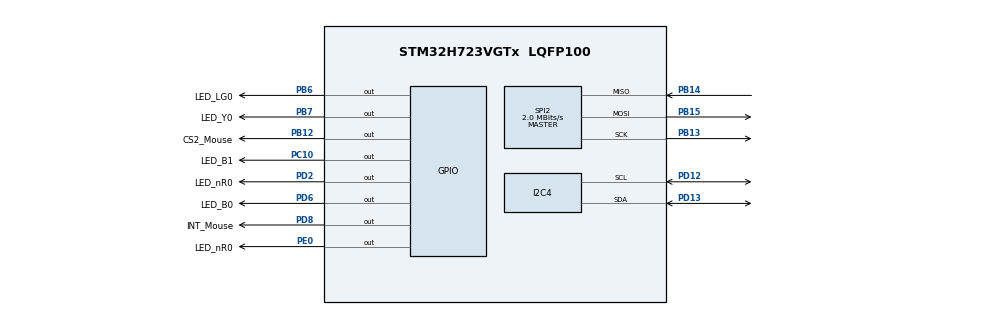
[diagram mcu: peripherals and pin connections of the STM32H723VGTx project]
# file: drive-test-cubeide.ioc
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CORTEX_M7.default_mode_Activation=1
I2C4.Timing=0x00303D5B
Mcu.Family=STM32H7
Mcu.Name=STM32H723VGTx
Mcu.Package=LQFP100
NVIC.PriorityGroup=NVIC_PRIORITYGROUP_4
PB12.GPIO_Label=CS2_Mouse
PB12.Signal=GPIO_Output
PB13.Mode=Full_Duplex_Master
PB13.Signal=SPI2_SCK
PB14.Mode=Full_Duplex_Master
PB14.Signal=SPI2_MISO
PB15.Mode=Full_Duplex_Master
PB15.Signal=SPI2_MOSI
PB6.GPIO_Label=LED_LG0
PB6.Signal=GPIO_Output
PB7.GPIO_Label=LED_Y0
PB7.Signal=GPIO_Output
PC10.GPIO_Label=LED_B1
PC10.Signal=GPIO_Output
PD12.Mode=I2C
PD12.Signal=I2C4_SCL
PD13.Mode=I2C
PD13.Signal=I2C4_SDA
PD2.GPIO_Label=LED_nR0
PD2.Signal=GPIO_Output
PD6.GPIO_Label=LED_B0
PD6.Signal=GPIO_Output
PD8.GPIO_Label=INT_Mouse
PD8.Signal=GPIO_Output
PE0.GPIO_Label=LED_nR0
PE0.Signal=GPIO_Output
PH0-OSC_IN.Mode=HSE-External-Oscillator
PH0-OSC_IN.Signal=RCC_OSC_IN
PH1-OSC_OUT.Mode=HSE-External-Oscillator
PH1-OSC_OUT.Signal=RCC_OSC_OUT
ProjectManager.HeapSize=0x200
ProjectManager.StackSize=0x400
ProjectManager.TargetToolchain=STM32CubeIDE
RCC.ADCFreq_Value=32250000
RCC.APB1Freq_Value=16000000
RCC.APB2Freq_Value=16000000
RCC.APB3Freq_Value=16000000
RCC.APB4Freq_Value=16000000
RCC.CortexFreq_Value=16000000
RCC.DIVM1=1
RCC.DIVN1=12
RCC.DIVQ1=3
RCC.HCLKFreq_Value=16000000
RCC.HSE_VALUE=16000000
RCC.PLLFRACN=0
RCC.PLLSourceVirtual=RCC_PLLSOURCE_HSE
RCC.SYSCLKFreq_VALUE=16000000
RCC.SYSCLKSource=RCC_SYSCLKSOURCE_HSE
RCC.USBFreq_Value=64000000
SPI2.BaudRatePrescaler=SPI_BAUDRATEPRESCALER_32
SPI2.CLKPhase=SPI_PHASE_1EDGE
SPI2.CalculateBaudRate=2.0 MBits/s
SPI2.DataSize=SPI_DATASIZE_8BIT
SPI2.Direction=SPI_DIRECTION_2LINES
SPI2.Mode=SPI_MODE_MASTER
SPI2.NSSPMode=SPI_NSS_PULSE_ENABLE
SPI2.VirtualType=VM_MASTER
VP_MEMORYMAP_VS_MEMORYMAP.Mode=CurAppReg
board=custom

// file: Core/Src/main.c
/* USER CODE BEGIN Header */
/**
  ******************************************************************************
  * @file           : main.c
  * @brief          : Main program body
  ******************************************************************************
  * @attention
  *
  * Copyright (c) 2025 STMicroelectronics.
  * All rights reserved.
  *
  * This software is licensed under terms that can be found in the LICENSE file
  * in the root directory of this software component.
  * If no LICENSE file comes with this software, it is provided AS-IS.
  *
  ******************************************************************************
  */
/* USER CODE END Header */
#include "main.h"
#include "i2c.h"
#include "memorymap.h"
#include "spi.h"
#include "gpio.h"

void SystemClock_Config(void);
static void MPU_Config(void);

int main(void)
{

  /* MPU Configuration--------------------------------------------------------*/
  MPU_Config();

  /* MCU Configuration--------------------------------------------------------*/

  /* Reset of all peripherals, Initializes the Flash interface and the Systick. */
  HAL_Init();

  /* Configure the system clock */
  SystemClock_Config();

  /* Initialize all configured peripherals */
  MX_GPIO_Init();
  MX_I2C4_Init();
  MX_SPI2_Init();
  /* USER CODE BEGIN 2 */
  UserApp_Init();

  /* USER CODE END 2 */

  /* Infinite loop */
  /* USER CODE BEGIN WHILE */
  while (1)
  {
      UserApp_Run();
    /* USER CODE END WHILE */

  }
}

void SystemClock_Config(void)
{
  RCC_OscInitTypeDef RCC_OscInitStruct = {0};
  RCC_ClkInitTypeDef RCC_ClkInitStruct = {0};

  /** Supply configuration update enable
  */
  HAL_PWREx_ConfigSupply(PWR_LDO_SUPPLY);

  /** Configure the main internal regulator output voltage
  */
  __HAL_PWR_VOLTAGESCALING_CONFIG(PWR_REGULATOR_VOLTAGE_SCALE3);

  while(!__HAL_PWR_GET_FLAG(PWR_FLAG_VOSRDY)) {}

  /** Initializes the RCC Oscillators according to the specified parameters
  * in the RCC_OscInitTypeDef structure.
  */
  RCC_OscInitStruct.OscillatorType = RCC_OSCILLATORTYPE_HSE;
  RCC_OscInitStruct.HSEState = RCC_HSE_ON;
  RCC_OscInitStruct.PLL.PLLState = RCC_PLL_ON;
  RCC_OscInitStruct.PLL.PLLSource = RCC_PLLSOURCE_HSE;
  RCC_OscInitStruct.PLL.PLLM = 1;
  RCC_OscInitStruct.PLL.PLLN = 12;
  RCC_OscInitStruct.PLL.PLLP = 2;
  RCC_OscInitStruct.PLL.PLLQ = 3;
  RCC_OscInitStruct.PLL.PLLR = 2;
  RCC_OscInitStruct.PLL.PLLRGE = RCC_PLL1VCIRANGE_3;
  RCC_OscInitStruct.PLL.PLLVCOSEL = RCC_PLL1VCOWIDE;
  RCC_OscInitStruct.PLL.PLLFRACN = 0;
  if (HAL_RCC_OscConfig(&RCC_OscInitStruct) != HAL_OK)
  {
    Error_Handler();
  }

  /** Initializes the CPU, AHB and APB buses clocks
  */
  RCC_ClkInitStruct.ClockType = RCC_CLOCKTYPE_HCLK|RCC_CLOCKTYPE_SYSCLK
                              |RCC_CLOCKTYPE_PCLK1|RCC_CLOCKTYPE_PCLK2
                              |RCC_CLOCKTYPE_D3PCLK1|RCC_CLOCKTYPE_D1PCLK1;
  RCC_ClkInitStruct.SYSCLKSource = RCC_SYSCLKSOURCE_HSE;
  RCC_ClkInitStruct.SYSCLKDivider = RCC_SYSCLK_DIV1;
  RCC_ClkInitStruct.AHBCLKDivider = RCC_HCLK_DIV1;
  RCC_ClkInitStruct.APB3CLKDivider = RCC_APB3_DIV1;
  RCC_ClkInitStruct.APB1CLKDivider = RCC_APB1_DIV1;
  RCC_ClkInitStruct.APB2CLKDivider = RCC_APB2_DIV1;
  RCC_ClkInitStruct.APB4CLKDivider = RCC_APB4_DIV1;

  if (HAL_RCC_ClockConfig(&RCC_ClkInitStruct, FLASH_LATENCY_0) != HAL_OK)
  {
    Error_Handler();
  }
}

 /* MPU Configuration */

void MPU_Config(void)
{
  MPU_Region_InitTypeDef MPU_InitStruct = {0};

  /* Disables the MPU */
  HAL_MPU_Disable();

  /** Initializes and configures the Region and the memory to be protected
  */
  MPU_InitStruct.Enable = MPU_REGION_ENABLE;
  MPU_InitStruct.Number = MPU_REGION_NUMBER0;
  MPU_InitStruct.BaseAddress = 0x0;
  MPU_InitStruct.Size = MPU_REGION_SIZE_4GB;
  MPU_InitStruct.SubRegionDisable = 0x87;
  MPU_InitStruct.TypeExtField = MPU_TEX_LEVEL0;
  MPU_InitStruct.AccessPermission = MPU_REGION_NO_ACCESS;
  MPU_InitStruct.DisableExec = MPU_INSTRUCTION_ACCESS_DISABLE;
  MPU_InitStruct.IsShareable = MPU_ACCESS_SHAREABLE;
  MPU_InitStruct.IsCacheable = MPU_ACCESS_NOT_CACHEABLE;
  MPU_InitStruct.IsBufferable = MPU_ACCESS_NOT_BUFFERABLE;

  HAL_MPU_ConfigRegion(&MPU_InitStruct);
  /* Enables the MPU */
  HAL_MPU_Enable(MPU_PRIVILEGED_DEFAULT);

}

void Error_Handler(void)
{
  __disable_irq();
  while (1)
  {
  }
}
